# M2354 register map
File version: 1.0
Registers are 32-bit, read-write, reset 0x0 unless marked. A register's access mark holds for its fields unless they carry their own. Offsets are from the block's base; [hi:lo] are bit positions.

## SYS_NS — SYS Register Map
Base 0x50000000
0x100 SYS_REGLCTLNS — Register Lock Control Register for Non-secure
  [7:0] REGLCTL — Register Lock Control Code. Some registers have write-protection function. Writing these registers have to disable the protected function by writing the sequence value '59h', '16h', '88h' to this field. After this sequence is completed, the REGLCTL bit will be set to 1 and write-protection registers can be normal write. REGLCTL[0]. Register Lock Control Disable Index
    0=Write-protection Enabled for writing protected registers. Any write to the protected register is ignored; 1=Write-protection Disabled for writing protected registers

## FVC — SCU Register Map
Base 0x4002F500
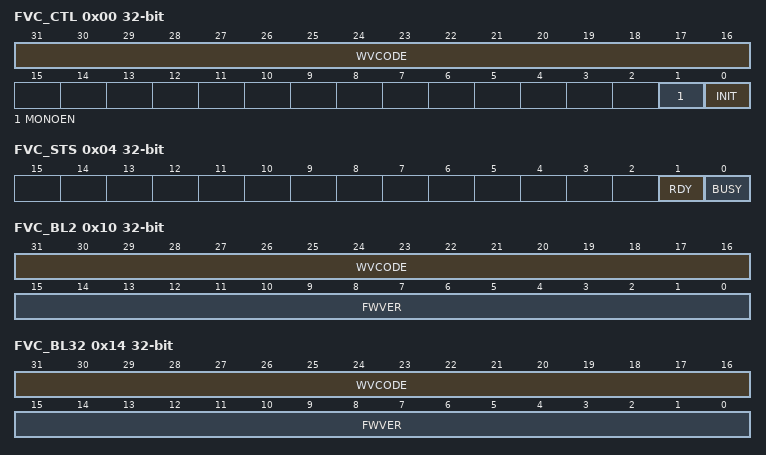
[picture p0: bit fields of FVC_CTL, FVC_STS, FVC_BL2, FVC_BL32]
0x00 FVC_CTL (reset mask 0xFFFFFFF0) — FVC Control Register
  [31:16] WVCODE — Verification Code. When written, this field must be 0x7710
  [1] MONOEN — Monotonic Enable Bit. Set to 1 to enable the monotonic mechanism of FVC. Note: This bit can be set to1 but cannot be cleared to 0.
  [0] INIT — FVC Init Bit. Set to 1 to enable FVC. This bit is writable when FVC is at Reset state. Note: After set to 1, this bit is cleared to 0 automatically when FVC is back to Reset state.
0x04 FVC_STS ro (reset mask 0xFFFFFFF0) — FVC Status Register
  [1] RDY — FVC Ready Bit. Indicates the FVC is ready after the initial process.
  [0] BUSY — FVC Busy Bit. Indicates the FVC is at busy state.
0x10 FVC_BL2 (reset mask 0xFFFF0000) — BL2 Firmware Control Register
  [31:16] WVCODE — Verification Code. When written, this field must be the current firmware version number
  [15:0] FWVER — Firmware Version. Read: Indicates the current firmware version of BL2. Write: Updates the firmware version of BL2. The maximum value of this field is 63.
0x14 FVC_BL32 (reset mask 0xFFFF0000) — BL32 Firmware Control Register
  [31:16] WVCODE — Verification Code. When written, this field must be the current firmware version number
  [15:0] FWVER — Firmware Version. Read: Indicates the current firmware version of BL32. Write: Updates the firmware version of BL32. The maximum value of this field is 63.
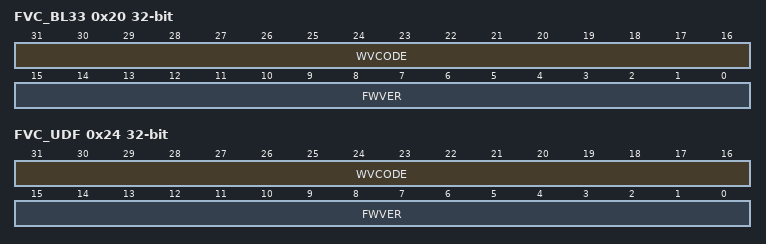
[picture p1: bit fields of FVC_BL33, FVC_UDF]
0x20 FVC_BL33 (reset mask 0xFFFF0000) — BL33 Firmware Control Register
  [31:16] WVCODE — Verification Code. When written, this field must be the current firmware version number
  [15:0] FWVER — Firmware Version. Read: Indicates the current firmware version of BL33. Write: Updates the firmware version of BL33. The maximum value of this field is 255.
0x24 FVC_UDF (reset mask 0xFFFF0000) — User-defined Firmware Control Register
  [31:16] WVCODE — Verification Code. When written, this field must be the current firmware version number
  [15:0] FWVER — Firmware Version. Read: Indicates the current firmware version of user's firmware. Write: Updates the firmware version of user's firmware. The maximum value of this field is 255.

## PLM — SCU Register Map
Base 0x4002F700
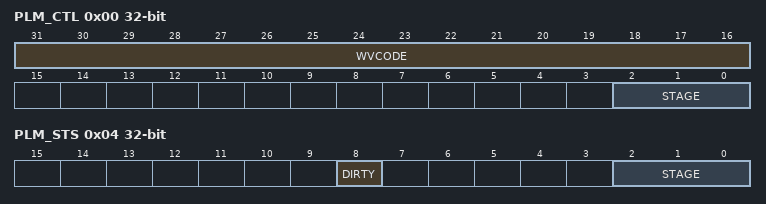
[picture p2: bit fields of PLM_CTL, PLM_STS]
0x00 PLM_CTL (reset mask 0xFFFFFFF0) — Product Life-cycle Control Register
  [31:16] WVCODE — Write Verify Code. The code is 0x475A for a valid write to this register.
  [2:0] STAGE — Life-cycle Stage Update Bits. Bits to update PLM stage. All bits can be set to one but cannot be cleared to 0. Other value will be ignored.
    1=progress to OEM stage; 3=progress to Deployed stage; 7=progress to RMA stage
0x04 PLM_STS ro (reset mask 0xFFFFFFF0) — Product Life-cycle Status Register
  [8] DIRTY — DIRTY Bit (Read Only). Indicate the life-cycle stage has been progressed after last cold-reset. Value of STAGE bits is not Current stage of PLM. It needs a cold reset to make it work.
  [2:0] STAGE — Life-cycle Stage (Read Only). Indicates the current stage of PLM.
    0=Vendor Stage; 1=OEM Stage; 3=Deployed Stage; 7=RMA Stage
